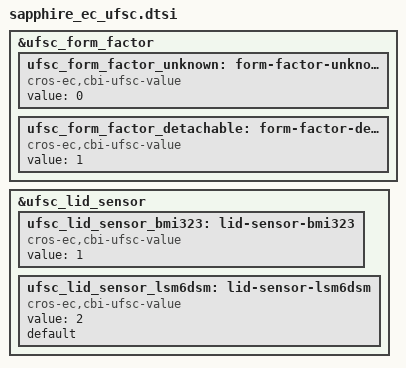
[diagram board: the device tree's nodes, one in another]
/* Auto-generated by generate_ufsc.py */

&ufsc_form_factor {
	ufsc_form_factor_unknown: form-factor-unknown {
		compatible = "cros-ec,cbi-ufsc-value";
		status = "okay";
		value = <0>;
	};
	ufsc_form_factor_detachable: form-factor-detachable {
		compatible = "cros-ec,cbi-ufsc-value";
		status = "okay";
		value = <1>;
	};
};

&ufsc_lid_sensor {
	ufsc_lid_sensor_bmi323: lid-sensor-bmi323 {
		compatible = "cros-ec,cbi-ufsc-value";
		status = "okay";
		value = <1>;
	};
	ufsc_lid_sensor_lsm6dsm: lid-sensor-lsm6dsm {
		compatible = "cros-ec,cbi-ufsc-value";
		status = "okay";
		value = <2>;
		default;
	};
};
